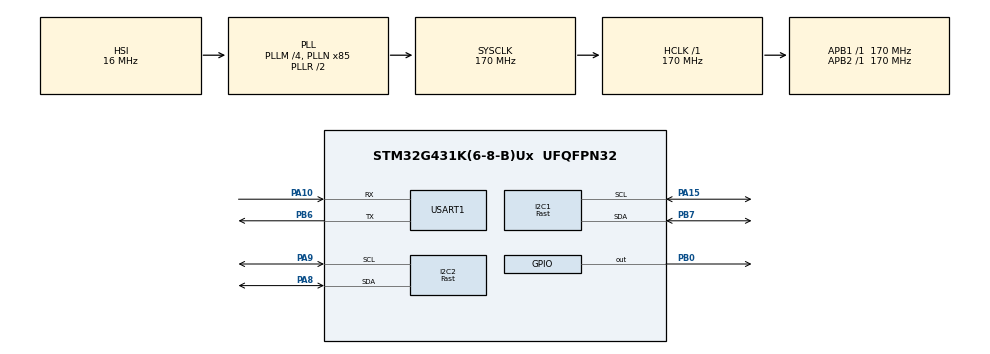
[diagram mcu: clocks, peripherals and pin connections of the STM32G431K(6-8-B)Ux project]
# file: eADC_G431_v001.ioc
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Dma.Request0=USART1_RX
Dma.Request1=USART1_TX
Dma.USART1_RX.0.Direction=DMA_PERIPH_TO_MEMORY
Dma.USART1_RX.0.EventEnable=DISABLE
Dma.USART1_RX.0.Instance=DMA1_Channel1
Dma.USART1_RX.0.MemDataAlignment=DMA_MDATAALIGN_BYTE
Dma.USART1_RX.0.MemInc=DMA_MINC_ENABLE
Dma.USART1_RX.0.Mode=DMA_NORMAL
Dma.USART1_RX.0.PeriphDataAlignment=DMA_PDATAALIGN_BYTE
Dma.USART1_RX.0.PeriphInc=DMA_PINC_DISABLE
Dma.USART1_RX.0.Polarity=HAL_DMAMUX_REQ_GEN_RISING
Dma.USART1_RX.0.Priority=DMA_PRIORITY_LOW
Dma.USART1_RX.0.RequestNumber=1
Dma.USART1_RX.0.SignalID=NONE
Dma.USART1_RX.0.SyncEnable=DISABLE
Dma.USART1_RX.0.SyncPolarity=HAL_DMAMUX_SYNC_NO_EVENT
Dma.USART1_RX.0.SyncRequestNumber=1
Dma.USART1_RX.0.SyncSignalID=NONE
Dma.USART1_TX.1.Direction=DMA_MEMORY_TO_PERIPH
Dma.USART1_TX.1.EventEnable=DISABLE
Dma.USART1_TX.1.Instance=DMA1_Channel2
Dma.USART1_TX.1.MemDataAlignment=DMA_MDATAALIGN_BYTE
Dma.USART1_TX.1.MemInc=DMA_MINC_ENABLE
Dma.USART1_TX.1.Mode=DMA_NORMAL
Dma.USART1_TX.1.PeriphDataAlignment=DMA_PDATAALIGN_BYTE
Dma.USART1_TX.1.PeriphInc=DMA_PINC_DISABLE
Dma.USART1_TX.1.Polarity=HAL_DMAMUX_REQ_GEN_RISING
Dma.USART1_TX.1.Priority=DMA_PRIORITY_LOW
Dma.USART1_TX.1.RequestNumber=1
Dma.USART1_TX.1.SignalID=NONE
Dma.USART1_TX.1.SyncEnable=DISABLE
Dma.USART1_TX.1.SyncPolarity=HAL_DMAMUX_SYNC_NO_EVENT
Dma.USART1_TX.1.SyncRequestNumber=1
Dma.USART1_TX.1.SyncSignalID=NONE
FREERTOS.INCLUDE_vTaskDelayUntil=1
FREERTOS.Tasks01=bmp2adsTask,0,512,task_BMP2ADS,As weak,NULL,Dynamic,NULL,NULL;iss2adsTask,0,512,task_ISS2ADS,As weak,NULL,Dynamic,NULL,NULL;flashTask,0,512,task_Flash,As weak,NULL,Dynamic,NULL,NULL
FREERTOS.configTOTAL_HEAP_SIZE=12288
FREERTOS.configUSE_NEWLIB_REENTRANT=1
I2C1.I2C_Speed_Mode=I2C_Fast
I2C1.Timing=0x40621236
I2C2.I2C_Speed_Mode=I2C_Fast
I2C2.Timing=0x40621236
IWDG.Prescaler=IWDG_PRESCALER_16
IWDG.Reload=2500
IWDG.Window=2500
Mcu.Family=STM32G4
Mcu.Name=STM32G431K(6-8-B)Ux
Mcu.Package=UFQFPN32
NVIC.DMA1_Channel1_IRQn=true\:5\:0\:false\:false\:true\:true\:false\:true\:true
NVIC.DMA1_Channel2_IRQn=true\:5\:0\:false\:false\:true\:true\:false\:true\:true
NVIC.PriorityGroup=NVIC_PRIORITYGROUP_4
NVIC.TIM1_UP_TIM16_IRQn=true\:15\:0\:false\:false\:true\:false\:false\:true\:true
NVIC.TimeBase=TIM1_UP_TIM16_IRQn
NVIC.TimeBaseIP=TIM1
NVIC.USART1_IRQn=true\:5\:0\:false\:false\:true\:true\:true\:true\:true
PA10.Mode=Asynchronous
PA10.Signal=USART1_RX
PA15.Mode=I2C
PA15.Signal=I2C1_SCL
PA8.Mode=I2C
PA8.Signal=I2C2_SDA
PA9.Mode=I2C
PA9.Signal=I2C2_SCL
PB0.Signal=GPIO_Output
PB6.Mode=Asynchronous
PB6.Signal=USART1_TX
PB7.Mode=I2C
PB7.Signal=I2C1_SDA
ProjectManager.HeapSize=0x200
ProjectManager.StackSize=0x400
ProjectManager.TargetToolchain=STM32CubeIDE
RCC.ADC12Freq_Value=170000000
RCC.AHBFreq_Value=170000000
RCC.APB1Freq_Value=170000000
RCC.APB1TimFreq_Value=170000000
RCC.APB2Freq_Value=170000000
RCC.APB2TimFreq_Value=170000000
RCC.CortexFreq_Value=170000000
RCC.EXTERNAL_CLOCK_VALUE=12288000
RCC.HCLKFreq_Value=170000000
RCC.HSE_VALUE=8000000
RCC.HSI48_VALUE=48000000
RCC.HSI_VALUE=16000000
RCC.LSE_VALUE=32768
RCC.PLLM=RCC_PLLM_DIV4
RCC.PLLN=85
RCC.SYSCLKFreq_VALUE=170000000
RCC.SYSCLKSource=RCC_SYSCLKSOURCE_PLLCLK
RCC.USBFreq_Value=170000000
RCC.VCOOutputFreq_Value=340000000
USART1.VirtualMode-Asynchronous=VM_ASYNC
VP_FREERTOS_VS_CMSIS_V1.Mode=CMSIS_V1
VP_IWDG_VS_IWDG.Mode=IWDG_Activate
VP_SYS_VS_DBSignals.Mode=DisableDeadBatterySignals
VP_SYS_VS_tim1.Mode=TIM1
board=custom

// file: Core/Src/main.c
/* USER CODE BEGIN Header */
/**
  ******************************************************************************
  * @file           : main.c
  * @brief          : Main program body
  ******************************************************************************
  * @attention
  *
  * Copyright (c) 2025 STMicroelectronics.
  * All rights reserved.
  *
  * This software is licensed under terms that can be found in the LICENSE file
  * in the root directory of this software component.
  * If no LICENSE file comes with this software, it is provided AS-IS.
  *
  ******************************************************************************
  */
/* USER CODE END Header */
#include "main.h"
#include "cmsis_os.h"
#include "app_config.h"  // for str_bit definition

I2C_HandleTypeDef hi2c1;
I2C_HandleTypeDef hi2c2;

IWDG_HandleTypeDef hiwdg;

UART_HandleTypeDef huart1;
DMA_HandleTypeDef hdma_usart1_rx;
DMA_HandleTypeDef hdma_usart1_tx;

osThreadId bmp2adsTaskHandle;
osThreadId iss2adsTaskHandle;
osThreadId flashTaskHandle;
/* USER CODE BEGIN PV */

extern str_bit CBIT, IBIT, PBIT; // share status bits (defined in task_BMP2ADS.c)

/* USER CODE END PV */

void SystemClock_Config(void);
static void MX_GPIO_Init(void);
static void MX_DMA_Init(void);
static void MX_USART1_UART_Init(void);
static void MX_I2C1_Init(void);
static void MX_I2C2_Init(void);
static void MX_IWDG_Init(void);
void task_BMP2ADS(void const * argument);
void task_ISS2ADS(void const * argument);
void task_Flash(void const * argument);

int main(void)
{

  /* MCU Configuration--------------------------------------------------------*/

  /* Reset of all peripherals, Initializes the Flash interface and the Systick. */
  HAL_Init();

  /* Configure the system clock */
  SystemClock_Config();

  /* Initialize all configured peripherals */
  MX_GPIO_Init();
  MX_DMA_Init();
  MX_USART1_UART_Init();
  MX_I2C1_Init();
  MX_I2C2_Init();
  MX_IWDG_Init();
  /* USER CODE BEGIN 2 */

  // Boot-time: set watchdog status flag in PBIT and then clear reset flags
  // Mapping kept as existing convention: 1 = normal (no watchdog reset), 0 = watchdog caused last reset
  if (__HAL_RCC_GET_FLAG(RCC_FLAG_IWDGRST)) {
      PBIT.watchdog_status = 1; // watchdog caused last reset
  } else {
      PBIT.watchdog_status = 0; // no watchdog reset
  }
  // Clear sticky reset flags so next boot reflects new reset causes only
  __HAL_RCC_CLEAR_RESET_FLAGS();

  /* USER CODE END 2 */

  /* Create the thread(s) */
  /* definition and creation of bmp2adsTask */
  osThreadDef(bmp2adsTask, task_BMP2ADS, osPriorityNormal, 0, 512);
  bmp2adsTaskHandle = osThreadCreate(osThread(bmp2adsTask), NULL);

  /* definition and creation of iss2adsTask */
  osThreadDef(iss2adsTask, task_ISS2ADS, osPriorityNormal, 0, 512);
  iss2adsTaskHandle = osThreadCreate(osThread(iss2adsTask), NULL);

  /* definition and creation of flashTask */
  osThreadDef(flashTask, task_Flash, osPriorityNormal, 0, 512);
  flashTaskHandle = osThreadCreate(osThread(flashTask), NULL);

  /* Start scheduler */
  osKernelStart();

  /* We should never get here as control is now taken by the scheduler */

  /* Infinite loop */
  while (1)
  {

  }
}

void SystemClock_Config(void)
{
  RCC_OscInitTypeDef RCC_OscInitStruct = {0};
  RCC_ClkInitTypeDef RCC_ClkInitStruct = {0};

  /** Configure the main internal regulator output voltage
  */
  HAL_PWREx_ControlVoltageScaling(PWR_REGULATOR_VOLTAGE_SCALE1_BOOST);

  /** Initializes the RCC Oscillators according to the specified parameters
  * in the RCC_OscInitTypeDef structure.
  */
  RCC_OscInitStruct.OscillatorType = RCC_OSCILLATORTYPE_HSI|RCC_OSCILLATORTYPE_LSI;
  RCC_OscInitStruct.HSIState = RCC_HSI_ON;
  RCC_OscInitStruct.HSICalibrationValue = RCC_HSICALIBRATION_DEFAULT;
  RCC_OscInitStruct.LSIState = RCC_LSI_ON;
  RCC_OscInitStruct.PLL.PLLState = RCC_PLL_ON;
  RCC_OscInitStruct.PLL.PLLSource = RCC_PLLSOURCE_HSI;
  RCC_OscInitStruct.PLL.PLLM = RCC_PLLM_DIV4;
  RCC_OscInitStruct.PLL.PLLN = 85;
  RCC_OscInitStruct.PLL.PLLP = RCC_PLLP_DIV2;
  RCC_OscInitStruct.PLL.PLLQ = RCC_PLLQ_DIV2;
  RCC_OscInitStruct.PLL.PLLR = RCC_PLLR_DIV2;
  if (HAL_RCC_OscConfig(&RCC_OscInitStruct) != HAL_OK)
  {
    Error_Handler();
  }

  /** Initializes the CPU, AHB and APB buses clocks
  */
  RCC_ClkInitStruct.ClockType = RCC_CLOCKTYPE_HCLK|RCC_CLOCKTYPE_SYSCLK
                              |RCC_CLOCKTYPE_PCLK1|RCC_CLOCKTYPE_PCLK2;
  RCC_ClkInitStruct.SYSCLKSource = RCC_SYSCLKSOURCE_PLLCLK;
  RCC_ClkInitStruct.AHBCLKDivider = RCC_SYSCLK_DIV1;
  RCC_ClkInitStruct.APB1CLKDivider = RCC_HCLK_DIV1;
  RCC_ClkInitStruct.APB2CLKDivider = RCC_HCLK_DIV1;

  if (HAL_RCC_ClockConfig(&RCC_ClkInitStruct, FLASH_LATENCY_4) != HAL_OK)
  {
    Error_Handler();
  }
}

static void MX_I2C1_Init(void)
{

  hi2c1.Instance = I2C1;
  hi2c1.Init.Timing = 0x40621236;
  hi2c1.Init.OwnAddress1 = 0;
  hi2c1.Init.AddressingMode = I2C_ADDRESSINGMODE_7BIT;
  hi2c1.Init.DualAddressMode = I2C_DUALADDRESS_DISABLE;
  hi2c1.Init.OwnAddress2 = 0;
  hi2c1.Init.OwnAddress2Masks = I2C_OA2_NOMASK;
  hi2c1.Init.GeneralCallMode = I2C_GENERALCALL_DISABLE;
  hi2c1.Init.NoStretchMode = I2C_NOSTRETCH_DISABLE;
  if (HAL_I2C_Init(&hi2c1) != HAL_OK)
  {
    Error_Handler();
  }

  /** Configure Analogue filter
  */
  if (HAL_I2CEx_ConfigAnalogFilter(&hi2c1, I2C_ANALOGFILTER_ENABLE) != HAL_OK)
  {
    Error_Handler();
  }

  /** Configure Digital filter
  */
  if (HAL_I2CEx_ConfigDigitalFilter(&hi2c1, 0) != HAL_OK)
  {
    Error_Handler();
  }

}

static void MX_I2C2_Init(void)
{

  hi2c2.Instance = I2C2;
  hi2c2.Init.Timing = 0x40621236;
  hi2c2.Init.OwnAddress1 = 0;
  hi2c2.Init.AddressingMode = I2C_ADDRESSINGMODE_7BIT;
  hi2c2.Init.DualAddressMode = I2C_DUALADDRESS_DISABLE;
  hi2c2.Init.OwnAddress2 = 0;
  hi2c2.Init.OwnAddress2Masks = I2C_OA2_NOMASK;
  hi2c2.Init.GeneralCallMode = I2C_GENERALCALL_DISABLE;
  hi2c2.Init.NoStretchMode = I2C_NOSTRETCH_DISABLE;
  if (HAL_I2C_Init(&hi2c2) != HAL_OK)
  {
    Error_Handler();
  }

  /** Configure Analogue filter
  */
  if (HAL_I2CEx_ConfigAnalogFilter(&hi2c2, I2C_ANALOGFILTER_ENABLE) != HAL_OK)
  {
    Error_Handler();
  }

  /** Configure Digital filter
  */
  if (HAL_I2CEx_ConfigDigitalFilter(&hi2c2, 0) != HAL_OK)
  {
    Error_Handler();
  }

}

static void MX_IWDG_Init(void)
{

  hiwdg.Instance = IWDG;
  hiwdg.Init.Prescaler = IWDG_PRESCALER_16;
  hiwdg.Init.Window = 2500;
  hiwdg.Init.Reload = 2500;
  if (HAL_IWDG_Init(&hiwdg) != HAL_OK)
  {
    Error_Handler();
  }

}

static void MX_USART1_UART_Init(void)
{

  huart1.Instance = USART1;
  huart1.Init.BaudRate = 115200;
  huart1.Init.WordLength = UART_WORDLENGTH_8B;
  huart1.Init.StopBits = UART_STOPBITS_1;
  huart1.Init.Parity = UART_PARITY_NONE;
  huart1.Init.Mode = UART_MODE_TX_RX;
  huart1.Init.HwFlowCtl = UART_HWCONTROL_NONE;
  huart1.Init.OverSampling = UART_OVERSAMPLING_16;
  huart1.Init.OneBitSampling = UART_ONE_BIT_SAMPLE_DISABLE;
  huart1.Init.ClockPrescaler = UART_PRESCALER_DIV1;
  huart1.AdvancedInit.AdvFeatureInit = UART_ADVFEATURE_NO_INIT;
  if (HAL_UART_Init(&huart1) != HAL_OK)
  {
    Error_Handler();
  }
  if (HAL_UARTEx_SetTxFifoThreshold(&huart1, UART_TXFIFO_THRESHOLD_1_8) != HAL_OK)
  {
    Error_Handler();
  }
  if (HAL_UARTEx_SetRxFifoThreshold(&huart1, UART_RXFIFO_THRESHOLD_1_8) != HAL_OK)
  {
    Error_Handler();
  }
  if (HAL_UARTEx_DisableFifoMode(&huart1) != HAL_OK)
  {
    Error_Handler();
  }

}

static void MX_DMA_Init(void)
{

  /* DMA controller clock enable */
  __HAL_RCC_DMAMUX1_CLK_ENABLE();
  __HAL_RCC_DMA1_CLK_ENABLE();

  /* DMA interrupt init */
  /* DMA1_Channel1_IRQn interrupt configuration */
  HAL_NVIC_SetPriority(DMA1_Channel1_IRQn, 5, 0);
  HAL_NVIC_EnableIRQ(DMA1_Channel1_IRQn);
  /* DMA1_Channel2_IRQn interrupt configuration */
  HAL_NVIC_SetPriority(DMA1_Channel2_IRQn, 5, 0);
  HAL_NVIC_EnableIRQ(DMA1_Channel2_IRQn);

}

static void MX_GPIO_Init(void)
{
  GPIO_InitTypeDef GPIO_InitStruct = {0};

  /* GPIO Ports Clock Enable */
  __HAL_RCC_GPIOB_CLK_ENABLE();
  __HAL_RCC_GPIOA_CLK_ENABLE();

  /*Configure GPIO pin Output Level */
  HAL_GPIO_WritePin(GPIOB, GPIO_PIN_0, GPIO_PIN_RESET);

  /*Configure GPIO pin : PB0 */
  GPIO_InitStruct.Pin = GPIO_PIN_0;
  GPIO_InitStruct.Mode = GPIO_MODE_OUTPUT_PP;
  GPIO_InitStruct.Pull = GPIO_NOPULL;
  GPIO_InitStruct.Speed = GPIO_SPEED_FREQ_LOW;
  HAL_GPIO_Init(GPIOB, &GPIO_InitStruct);

}

__weak void task_BMP2ADS(void const * argument)
{
  for(;;)
  {
    osDelay(1);
  }
}

__weak void task_ISS2ADS(void const * argument)
{
  for(;;)
  {
    osDelay(1);
  }
}

__weak void task_Flash(void const * argument)
{
  for(;;)
  {
    osDelay(1);
  }
}

void HAL_TIM_PeriodElapsedCallback(TIM_HandleTypeDef *htim)
{
  if (htim->Instance == TIM1)
  {
    HAL_IncTick();
  }
}

void Error_Handler(void)
{
  __disable_irq();
  while (1)
  {
  }
}
